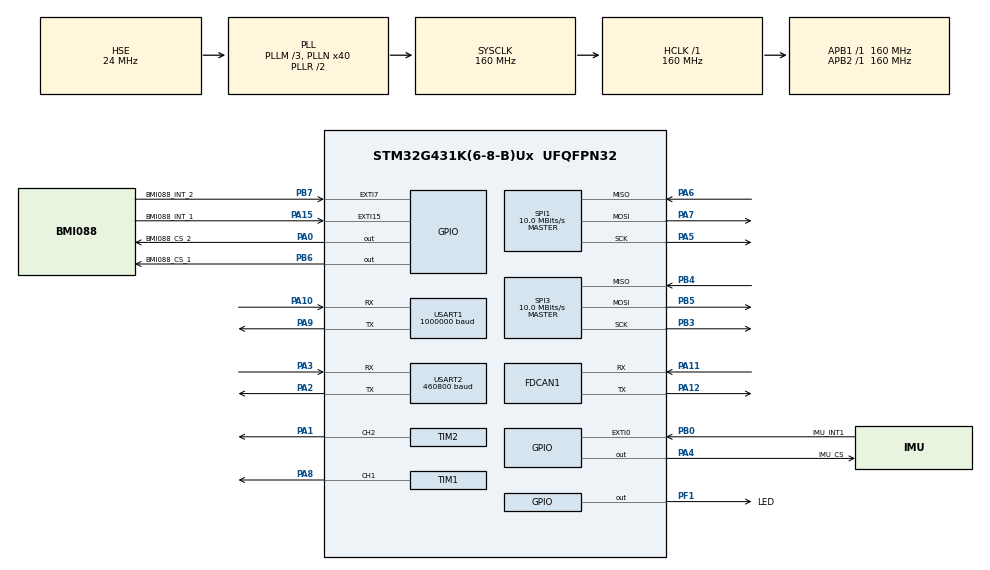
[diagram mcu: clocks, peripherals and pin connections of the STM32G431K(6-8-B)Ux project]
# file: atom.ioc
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Dma.Request0=USART2_RX
Dma.Request1=USART2_TX
Dma.Request2=SPI1_RX
Dma.Request3=SPI1_TX
Dma.Request4=USART1_RX
Dma.Request5=USART1_TX
Dma.Request6=SPI3_RX
Dma.Request7=SPI3_TX
Dma.SPI1_RX.2.Direction=DMA_PERIPH_TO_MEMORY
Dma.SPI1_RX.2.EventEnable=DISABLE
Dma.SPI1_RX.2.Instance=DMA1_Channel5
Dma.SPI1_RX.2.MemDataAlignment=DMA_MDATAALIGN_BYTE
Dma.SPI1_RX.2.MemInc=DMA_MINC_ENABLE
Dma.SPI1_RX.2.Mode=DMA_NORMAL
Dma.SPI1_RX.2.PeriphDataAlignment=DMA_PDATAALIGN_BYTE
Dma.SPI1_RX.2.PeriphInc=DMA_PINC_DISABLE
Dma.SPI1_RX.2.Polarity=HAL_DMAMUX_REQ_GEN_RISING
Dma.SPI1_RX.2.Priority=DMA_PRIORITY_LOW
Dma.SPI1_RX.2.RequestNumber=1
Dma.SPI1_RX.2.SignalID=NONE
Dma.SPI1_RX.2.SyncEnable=DISABLE
Dma.SPI1_RX.2.SyncPolarity=HAL_DMAMUX_SYNC_NO_EVENT
Dma.SPI1_RX.2.SyncRequestNumber=1
Dma.SPI1_RX.2.SyncSignalID=NONE
Dma.SPI1_TX.3.Direction=DMA_MEMORY_TO_PERIPH
Dma.SPI1_TX.3.EventEnable=DISABLE
Dma.SPI1_TX.3.Instance=DMA1_Channel6
Dma.SPI1_TX.3.MemDataAlignment=DMA_MDATAALIGN_BYTE
Dma.SPI1_TX.3.MemInc=DMA_MINC_ENABLE
Dma.SPI1_TX.3.Mode=DMA_NORMAL
Dma.SPI1_TX.3.PeriphDataAlignment=DMA_PDATAALIGN_BYTE
Dma.SPI1_TX.3.PeriphInc=DMA_PINC_DISABLE
Dma.SPI1_TX.3.Polarity=HAL_DMAMUX_REQ_GEN_RISING
Dma.SPI1_TX.3.Priority=DMA_PRIORITY_LOW
Dma.SPI1_TX.3.RequestNumber=1
Dma.SPI1_TX.3.SignalID=NONE
Dma.SPI1_TX.3.SyncEnable=DISABLE
Dma.SPI1_TX.3.SyncPolarity=HAL_DMAMUX_SYNC_NO_EVENT
Dma.SPI1_TX.3.SyncRequestNumber=1
Dma.SPI1_TX.3.SyncSignalID=NONE
Dma.SPI3_RX.6.Direction=DMA_PERIPH_TO_MEMORY
Dma.SPI3_RX.6.EventEnable=DISABLE
Dma.SPI3_RX.6.Instance=DMA1_Channel3
Dma.SPI3_RX.6.MemDataAlignment=DMA_MDATAALIGN_BYTE
Dma.SPI3_RX.6.MemInc=DMA_MINC_ENABLE
Dma.SPI3_RX.6.Mode=DMA_NORMAL
Dma.SPI3_RX.6.PeriphDataAlignment=DMA_PDATAALIGN_BYTE
Dma.SPI3_RX.6.PeriphInc=DMA_PINC_DISABLE
Dma.SPI3_RX.6.Polarity=HAL_DMAMUX_REQ_GEN_RISING
Dma.SPI3_RX.6.Priority=DMA_PRIORITY_LOW
Dma.SPI3_RX.6.RequestNumber=1
Dma.SPI3_RX.6.SignalID=NONE
Dma.SPI3_RX.6.SyncEnable=DISABLE
Dma.SPI3_RX.6.SyncPolarity=HAL_DMAMUX_SYNC_NO_EVENT
Dma.SPI3_RX.6.SyncRequestNumber=1
Dma.SPI3_RX.6.SyncSignalID=NONE
Dma.SPI3_TX.7.Direction=DMA_MEMORY_TO_PERIPH
Dma.SPI3_TX.7.EventEnable=DISABLE
Dma.SPI3_TX.7.Instance=DMA1_Channel4
Dma.SPI3_TX.7.MemDataAlignment=DMA_MDATAALIGN_BYTE
Dma.SPI3_TX.7.MemInc=DMA_MINC_ENABLE
Dma.SPI3_TX.7.Mode=DMA_NORMAL
Dma.SPI3_TX.7.PeriphDataAlignment=DMA_PDATAALIGN_BYTE
Dma.SPI3_TX.7.PeriphInc=DMA_PINC_DISABLE
Dma.SPI3_TX.7.Polarity=HAL_DMAMUX_REQ_GEN_RISING
Dma.SPI3_TX.7.Priority=DMA_PRIORITY_LOW
Dma.SPI3_TX.7.RequestNumber=1
Dma.SPI3_TX.7.SignalID=NONE
Dma.SPI3_TX.7.SyncEnable=DISABLE
Dma.SPI3_TX.7.SyncPolarity=HAL_DMAMUX_SYNC_NO_EVENT
Dma.SPI3_TX.7.SyncRequestNumber=1
Dma.SPI3_TX.7.SyncSignalID=NONE
Dma.USART1_RX.4.Direction=DMA_PERIPH_TO_MEMORY
Dma.USART1_RX.4.EventEnable=DISABLE
Dma.USART1_RX.4.Instance=DMA2_Channel1
Dma.USART1_RX.4.MemDataAlignment=DMA_MDATAALIGN_BYTE
Dma.USART1_RX.4.MemInc=DMA_MINC_ENABLE
Dma.USART1_RX.4.Mode=DMA_NORMAL
Dma.USART1_RX.4.PeriphDataAlignment=DMA_PDATAALIGN_BYTE
Dma.USART1_RX.4.PeriphInc=DMA_PINC_DISABLE
Dma.USART1_RX.4.Polarity=HAL_DMAMUX_REQ_GEN_RISING
Dma.USART1_RX.4.Priority=DMA_PRIORITY_LOW
Dma.USART1_RX.4.RequestNumber=1
Dma.USART1_RX.4.SignalID=NONE
Dma.USART1_RX.4.SyncEnable=DISABLE
Dma.USART1_RX.4.SyncPolarity=HAL_DMAMUX_SYNC_NO_EVENT
Dma.USART1_RX.4.SyncRequestNumber=1
Dma.USART1_RX.4.SyncSignalID=NONE
Dma.USART1_TX.5.Direction=DMA_MEMORY_TO_PERIPH
Dma.USART1_TX.5.EventEnable=DISABLE
Dma.USART1_TX.5.Instance=DMA2_Channel2
Dma.USART1_TX.5.MemDataAlignment=DMA_MDATAALIGN_BYTE
Dma.USART1_TX.5.MemInc=DMA_MINC_ENABLE
Dma.USART1_TX.5.Mode=DMA_NORMAL
Dma.USART1_TX.5.PeriphDataAlignment=DMA_PDATAALIGN_BYTE
Dma.USART1_TX.5.PeriphInc=DMA_PINC_DISABLE
Dma.USART1_TX.5.Polarity=HAL_DMAMUX_REQ_GEN_RISING
Dma.USART1_TX.5.Priority=DMA_PRIORITY_LOW
Dma.USART1_TX.5.RequestNumber=1
Dma.USART1_TX.5.SignalID=NONE
Dma.USART1_TX.5.SyncEnable=DISABLE
Dma.USART1_TX.5.SyncPolarity=HAL_DMAMUX_SYNC_NO_EVENT
Dma.USART1_TX.5.SyncRequestNumber=1
Dma.USART1_TX.5.SyncSignalID=NONE
Dma.USART2_RX.0.Direction=DMA_PERIPH_TO_MEMORY
Dma.USART2_RX.0.EventEnable=DISABLE
Dma.USART2_RX.0.Instance=DMA1_Channel1
Dma.USART2_RX.0.MemDataAlignment=DMA_MDATAALIGN_BYTE
Dma.USART2_RX.0.MemInc=DMA_MINC_ENABLE
Dma.USART2_RX.0.Mode=DMA_NORMAL
Dma.USART2_RX.0.PeriphDataAlignment=DMA_PDATAALIGN_BYTE
Dma.USART2_RX.0.PeriphInc=DMA_PINC_DISABLE
Dma.USART2_RX.0.Polarity=HAL_DMAMUX_REQ_GEN_RISING
Dma.USART2_RX.0.Priority=DMA_PRIORITY_LOW
Dma.USART2_RX.0.RequestNumber=1
Dma.USART2_RX.0.SignalID=NONE
Dma.USART2_RX.0.SyncEnable=DISABLE
Dma.USART2_RX.0.SyncPolarity=HAL_DMAMUX_SYNC_NO_EVENT
Dma.USART2_RX.0.SyncRequestNumber=1
Dma.USART2_RX.0.SyncSignalID=NONE
Dma.USART2_TX.1.Direction=DMA_MEMORY_TO_PERIPH
Dma.USART2_TX.1.EventEnable=DISABLE
Dma.USART2_TX.1.Instance=DMA1_Channel2
Dma.USART2_TX.1.MemDataAlignment=DMA_MDATAALIGN_BYTE
Dma.USART2_TX.1.MemInc=DMA_MINC_ENABLE
Dma.USART2_TX.1.Mode=DMA_NORMAL
Dma.USART2_TX.1.PeriphDataAlignment=DMA_PDATAALIGN_BYTE
Dma.USART2_TX.1.PeriphInc=DMA_PINC_DISABLE
Dma.USART2_TX.1.Polarity=HAL_DMAMUX_REQ_GEN_RISING
Dma.USART2_TX.1.Priority=DMA_PRIORITY_LOW
Dma.USART2_TX.1.RequestNumber=1
Dma.USART2_TX.1.SignalID=NONE
Dma.USART2_TX.1.SyncEnable=DISABLE
Dma.USART2_TX.1.SyncPolarity=HAL_DMAMUX_SYNC_NO_EVENT
Dma.USART2_TX.1.SyncRequestNumber=1
Dma.USART2_TX.1.SyncSignalID=NONE
FDCAN1.AutoRetransmission=ENABLE
FDCAN1.CalculateBaudRateNominal=1000000
FDCAN1.CalculateTimeBitNominal=1000
FDCAN1.CalculateTimeQuantumNominal=62.5
FDCAN1.DataPrescaler=2
FDCAN1.DataSyncJumpWidth=4
FDCAN1.DataTimeSeg1=13
FDCAN1.DataTimeSeg2=2
FDCAN1.ExtFiltersNbr=2
FDCAN1.FrameFormat=FDCAN_FRAME_FD_BRS
FDCAN1.Mode=FDCAN_MODE_NORMAL
FDCAN1.NominalPrescaler=10
FDCAN1.NominalSyncJumpWidth=4
FDCAN1.NominalTimeSeg1=13
FDCAN1.NominalTimeSeg2=2
FDCAN1.StdFiltersNbr=2
FDCAN1.TransmitPause=DISABLE
FREERTOS.INCLUDE_uxTaskPriorityGet=0
FREERTOS.INCLUDE_vTaskDelayUntil=1
FREERTOS.INCLUDE_vTaskDelete=0
FREERTOS.INCLUDE_vTaskPrioritySet=0
FREERTOS.INCLUDE_vTaskSuspend=0
FREERTOS.Tasks01=defaultTask,0,1024,StartDefaultTask,Default,NULL,Dynamic,NULL,NULL
FREERTOS.configENABLE_BACKWARD_COMPATIBILITY=0
FREERTOS.configENABLE_FPU=1
FREERTOS.configTOTAL_HEAP_SIZE=0x6000
FREERTOS.configUSE_COUNTING_SEMAPHORES=1
FREERTOS.configUSE_MUTEXES=1
Mcu.Family=STM32G4
Mcu.Name=STM32G431K(6-8-B)Ux
Mcu.Package=UFQFPN32
NVIC.DMA1_Channel1_IRQn=true\:5\:0\:true\:false\:true\:true\:false\:true\:true
NVIC.DMA1_Channel2_IRQn=true\:5\:0\:true\:false\:true\:true\:false\:true\:true
NVIC.DMA1_Channel3_IRQn=true\:5\:0\:true\:false\:true\:true\:false\:true\:true
NVIC.DMA1_Channel4_IRQn=true\:5\:0\:true\:false\:true\:true\:false\:true\:true
NVIC.DMA1_Channel5_IRQn=true\:5\:0\:true\:false\:true\:true\:false\:true\:true
NVIC.DMA1_Channel6_IRQn=true\:5\:0\:true\:false\:true\:true\:false\:true\:true
NVIC.DMA2_Channel1_IRQn=true\:5\:0\:true\:false\:true\:true\:false\:true\:true
NVIC.DMA2_Channel2_IRQn=true\:5\:0\:true\:false\:true\:true\:false\:true\:true
NVIC.EXTI0_IRQn=true\:5\:0\:true\:false\:true\:true\:true\:true\:true
NVIC.EXTI15_10_IRQn=true\:5\:0\:true\:false\:true\:true\:true\:true\:true
NVIC.EXTI9_5_IRQn=true\:5\:0\:true\:false\:true\:true\:true\:true\:true
NVIC.FDCAN1_IT0_IRQn=true\:5\:0\:true\:false\:true\:true\:true\:true\:true
NVIC.FDCAN1_IT1_IRQn=true\:5\:0\:true\:false\:true\:true\:true\:true\:true
NVIC.PriorityGroup=NVIC_PRIORITYGROUP_4
NVIC.RCC_IRQn=true\:5\:0\:true\:false\:true\:true\:true\:false\:true
NVIC.SPI1_IRQn=true\:5\:0\:true\:false\:true\:true\:true\:true\:true
NVIC.SPI3_IRQn=true\:5\:0\:true\:false\:true\:true\:true\:true\:true
NVIC.TIM1_BRK_TIM15_IRQn=true\:15\:0\:true\:false\:true\:false\:false\:true\:true
NVIC.TIM3_IRQn=true\:0\:0\:true\:false\:true\:false\:false\:true\:true
NVIC.TimeBase=TIM3_IRQn
NVIC.TimeBaseIP=TIM3
NVIC.USART1_IRQn=true\:5\:0\:true\:false\:true\:true\:true\:true\:true
NVIC.USART2_IRQn=true\:5\:0\:true\:false\:true\:true\:true\:true\:true
PA0.GPIO_Label=BMI088_CS_2
PA0.PinState=GPIO_PIN_SET
PA0.Signal=GPIO_Output
PA1.Signal=S_TIM2_CH2
PA10.Mode=Asynchronous
PA10.Signal=USART1_RX
PA11.Mode=FDCAN_Activate
PA11.Signal=FDCAN1_RX
PA12.Mode=FDCAN_Activate
PA12.Signal=FDCAN1_TX
PA13.Mode=Serial_Wire
PA13.Signal=SYS_JTMS-SWDIO
PA14.Mode=Serial_Wire
PA14.Signal=SYS_JTCK-SWCLK
PA15.GPIO_Label=BMI088_INT_1
PA15.GPIO_ModeDefaultEXTI=GPIO_MODE_IT_FALLING
PA15.Signal=GPXTI15
PA2.Mode=Asynchronous
PA2.Signal=USART2_TX
PA3.Mode=Asynchronous
PA3.Signal=USART2_RX
PA4.GPIO_Label=IMU_CS
PA4.PinState=GPIO_PIN_SET
PA4.Signal=GPIO_Output
PA5.GPIO_PuPd=GPIO_PULLUP
PA5.Mode=Full_Duplex_Master
PA5.Signal=SPI1_SCK
PA6.GPIO_PuPd=GPIO_PULLDOWN
PA6.Mode=Full_Duplex_Master
PA6.Signal=SPI1_MISO
PA7.GPIO_PuPd=GPIO_PULLUP
PA7.Mode=Full_Duplex_Master
PA7.Signal=SPI1_MOSI
PA8.Signal=S_TIM1_CH1
PA9.Mode=Asynchronous
PA9.Signal=USART1_TX
PB0.GPIO_Label=IMU_INT1
PB0.GPIO_ModeDefaultEXTI=GPIO_MODE_IT_FALLING
PB0.GPIO_PuPd=GPIO_PULLDOWN
PB0.Signal=GPXTI0
PB3.Mode=Full_Duplex_Master
PB3.Signal=SPI3_SCK
PB4.Mode=Full_Duplex_Master
PB4.Signal=SPI3_MISO
PB5.Mode=Full_Duplex_Master
PB5.Signal=SPI3_MOSI
PB6.GPIO_Label=BMI088_CS_1
PB6.PinState=GPIO_PIN_SET
PB6.Signal=GPIO_Output
PB7.GPIO_Label=BMI088_INT_2
PB7.GPIO_ModeDefaultEXTI=GPIO_MODE_IT_FALLING
PB7.Signal=GPXTI7
PF0-OSC_IN.Mode=HSE-External-Clock-Source
PF0-OSC_IN.Signal=RCC_OSC_IN
PF1-OSC_OUT.GPIO_Label=LED
PF1-OSC_OUT.Signal=GPIO_Output
ProjectManager.HeapSize=0x200
ProjectManager.StackSize=0x400
ProjectManager.TargetToolchain=CMake
RCC.ADC12Freq_Value=160000000
RCC.AHBFreq_Value=160000000
RCC.APB1Freq_Value=160000000
RCC.APB1TimFreq_Value=160000000
RCC.APB2Freq_Value=160000000
RCC.APB2TimFreq_Value=160000000
RCC.CortexFreq_Value=160000000
RCC.EXTERNAL_CLOCK_VALUE=12288000
RCC.HCLKFreq_Value=160000000
RCC.HSE_VALUE=24000000
RCC.HSI48_VALUE=48000000
RCC.HSI_VALUE=16000000
RCC.LSE_VALUE=32768
RCC.PLLM=RCC_PLLM_DIV3
RCC.PLLN=40
RCC.PLLSourceVirtual=RCC_PLLSOURCE_HSE
RCC.SYSCLKFreq_VALUE=160000000
RCC.SYSCLKSource=RCC_SYSCLKSOURCE_PLLCLK
RCC.USBFreq_Value=160000000
RCC.VCOOutputFreq_Value=320000000
SH.S_TIM1_CH1.0=TIM1_CH1,PWM Generation1 CH1
SH.S_TIM2_CH2.0=TIM2_CH2,PWM Generation2 CH2
SPI1.BaudRatePrescaler=SPI_BAUDRATEPRESCALER_16
SPI1.CLKPhase=SPI_PHASE_1EDGE
SPI1.CLKPolarity=SPI_POLARITY_LOW
SPI1.CalculateBaudRate=10.0 MBits/s
SPI1.DataSize=SPI_DATASIZE_8BIT
SPI1.Direction=SPI_DIRECTION_2LINES
SPI1.Mode=SPI_MODE_MASTER
SPI1.VirtualType=VM_MASTER
SPI3.BaudRatePrescaler=SPI_BAUDRATEPRESCALER_16
SPI3.CLKPhase=SPI_PHASE_2EDGE
SPI3.CLKPolarity=SPI_POLARITY_HIGH
SPI3.CalculateBaudRate=10.0 MBits/s
SPI3.DataSize=SPI_DATASIZE_8BIT
SPI3.Direction=SPI_DIRECTION_2LINES
SPI3.Mode=SPI_MODE_MASTER
SPI3.VirtualType=VM_MASTER
TIM1.Channel-PWM\ Generation1\ CH1=TIM_CHANNEL_1
TIM1.PeriodNoDither=99
TIM2.Channel-PWM\ Generation2\ CH2=TIM_CHANNEL_2
TIM2.PeriodNoDither=99
TIM8.AutoReloadPreload=TIM_AUTORELOAD_PRELOAD_DISABLE
TIM8.ClockDivision=TIM_CLOCKDIVISION_DIV1
TIM8.Prescaler=159
USART1.BaudRate=1000000
USART1.VirtualMode-Asynchronous=VM_ASYNC
USART2.BaudRate=460800
USART2.VirtualMode-Asynchronous=VM_ASYNC
VP_FREERTOS_VS_CMSIS_V1.Mode=CMSIS_V1
VP_SYS_VS_DBSignals.Mode=DisableDeadBatterySignals
VP_SYS_VS_tim3.Mode=TIM3
VP_TIM8_VS_ClockSourceINT.Mode=Internal
board=custom

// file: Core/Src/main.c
/* USER CODE BEGIN Header */
/**
  ******************************************************************************
  * @file           : main.c
  * @brief          : Main program body
  ******************************************************************************
  * @attention
  *
  * Copyright (c) 2025 STMicroelectronics.
  * All rights reserved.
  *
  * This software is licensed under terms that can be found in the LICENSE file
  * in the root directory of this software component.
  * If no LICENSE file comes with this software, it is provided AS-IS.
  *
  ******************************************************************************
  */
/* USER CODE END Header */
#include "main.h"
#include "cmsis_os.h"

FDCAN_HandleTypeDef hfdcan1;

SPI_HandleTypeDef hspi1;
SPI_HandleTypeDef hspi3;
DMA_HandleTypeDef hdma_spi1_rx;
DMA_HandleTypeDef hdma_spi1_tx;
DMA_HandleTypeDef hdma_spi3_rx;
DMA_HandleTypeDef hdma_spi3_tx;

TIM_HandleTypeDef htim1;
TIM_HandleTypeDef htim2;
TIM_HandleTypeDef htim8;

UART_HandleTypeDef huart1;
UART_HandleTypeDef huart2;
DMA_HandleTypeDef hdma_usart1_rx;
DMA_HandleTypeDef hdma_usart1_tx;
DMA_HandleTypeDef hdma_usart2_rx;
DMA_HandleTypeDef hdma_usart2_tx;

osThreadId defaultTaskHandle;

void SystemClock_Config(void);
void StartDefaultTask(void const * argument);

/* USER CODE BEGIN 0 */
__attribute__((section(".reboot_in_bootloader_section"), used)) static void
bsp_reboot_in_bootloader(void);
/* USER CODE END 0 */

int main(void)
{

  /* MCU Configuration--------------------------------------------------------*/

  /* Reset of all peripherals, Initializes the Flash interface and the Systick. */
  HAL_Init();

  /* Configure the system clock */
  SystemClock_Config();

  /* Initialize all configured peripherals */
  MX_GPIO_Init();
  MX_DMA_Init();
  MX_FDCAN1_Init();
  MX_SPI1_Init();
  MX_USART2_UART_Init();
  MX_USART1_UART_Init();
  MX_TIM2_Init();
  MX_SPI3_Init();
  MX_TIM1_Init();
  MX_TIM8_Init();

  /* Create the thread(s) */
  /* definition and creation of defaultTask */
  osThreadDef(defaultTask, StartDefaultTask, osPriorityNormal, 0, 1024);
  defaultTaskHandle = osThreadCreate(osThread(defaultTask), NULL);

  /* Start scheduler */
  osKernelStart();

  /* We should never get here as control is now taken by the scheduler */

  /* Infinite loop */
  while (1)
  {

  }
}

void SystemClock_Config(void)
{
  RCC_OscInitTypeDef RCC_OscInitStruct = {0};
  RCC_ClkInitTypeDef RCC_ClkInitStruct = {0};

  /** Configure the main internal regulator output voltage
  */
  HAL_PWREx_ControlVoltageScaling(PWR_REGULATOR_VOLTAGE_SCALE1_BOOST);

  /** Initializes the RCC Oscillators according to the specified parameters
  * in the RCC_OscInitTypeDef structure.
  */
  RCC_OscInitStruct.OscillatorType = RCC_OSCILLATORTYPE_HSE;
  RCC_OscInitStruct.HSEState = RCC_HSE_BYPASS;
  RCC_OscInitStruct.PLL.PLLState = RCC_PLL_ON;
  RCC_OscInitStruct.PLL.PLLSource = RCC_PLLSOURCE_HSE;
  RCC_OscInitStruct.PLL.PLLM = RCC_PLLM_DIV3;
  RCC_OscInitStruct.PLL.PLLN = 40;
  RCC_OscInitStruct.PLL.PLLP = RCC_PLLP_DIV2;
  RCC_OscInitStruct.PLL.PLLQ = RCC_PLLQ_DIV2;
  RCC_OscInitStruct.PLL.PLLR = RCC_PLLR_DIV2;
  if (HAL_RCC_OscConfig(&RCC_OscInitStruct) != HAL_OK)
  {
    Error_Handler();
  }

  /** Initializes the CPU, AHB and APB buses clocks
  */
  RCC_ClkInitStruct.ClockType = RCC_CLOCKTYPE_HCLK|RCC_CLOCKTYPE_SYSCLK
                              |RCC_CLOCKTYPE_PCLK1|RCC_CLOCKTYPE_PCLK2;
  RCC_ClkInitStruct.SYSCLKSource = RCC_SYSCLKSOURCE_PLLCLK;
  RCC_ClkInitStruct.AHBCLKDivider = RCC_SYSCLK_DIV1;
  RCC_ClkInitStruct.APB1CLKDivider = RCC_HCLK_DIV1;
  RCC_ClkInitStruct.APB2CLKDivider = RCC_HCLK_DIV1;

  if (HAL_RCC_ClockConfig(&RCC_ClkInitStruct, FLASH_LATENCY_4) != HAL_OK)
  {
    Error_Handler();
  }
}

void MX_FDCAN1_Init(void)
{

  hfdcan1.Instance = FDCAN1;
  hfdcan1.Init.ClockDivider = FDCAN_CLOCK_DIV1;
  hfdcan1.Init.FrameFormat = FDCAN_FRAME_FD_BRS;
  hfdcan1.Init.Mode = FDCAN_MODE_NORMAL;
  hfdcan1.Init.AutoRetransmission = ENABLE;
  hfdcan1.Init.TransmitPause = DISABLE;
  hfdcan1.Init.ProtocolException = DISABLE;
  hfdcan1.Init.NominalPrescaler = 10;
  hfdcan1.Init.NominalSyncJumpWidth = 4;
  hfdcan1.Init.NominalTimeSeg1 = 13;
  hfdcan1.Init.NominalTimeSeg2 = 2;
  hfdcan1.Init.DataPrescaler = 2;
  hfdcan1.Init.DataSyncJumpWidth = 4;
  hfdcan1.Init.DataTimeSeg1 = 13;
  hfdcan1.Init.DataTimeSeg2 = 2;
  hfdcan1.Init.StdFiltersNbr = 2;
  hfdcan1.Init.ExtFiltersNbr = 2;
  hfdcan1.Init.TxFifoQueueMode = FDCAN_TX_FIFO_OPERATION;
  if (HAL_FDCAN_Init(&hfdcan1) != HAL_OK)
  {
    Error_Handler();
  }

}

void MX_SPI1_Init(void)
{

  /* SPI1 parameter configuration*/
  hspi1.Instance = SPI1;
  hspi1.Init.Mode = SPI_MODE_MASTER;
  hspi1.Init.Direction = SPI_DIRECTION_2LINES;
  hspi1.Init.DataSize = SPI_DATASIZE_8BIT;
  hspi1.Init.CLKPolarity = SPI_POLARITY_LOW;
  hspi1.Init.CLKPhase = SPI_PHASE_1EDGE;
  hspi1.Init.NSS = SPI_NSS_SOFT;
  hspi1.Init.BaudRatePrescaler = SPI_BAUDRATEPRESCALER_16;
  hspi1.Init.FirstBit = SPI_FIRSTBIT_MSB;
  hspi1.Init.TIMode = SPI_TIMODE_DISABLE;
  hspi1.Init.CRCCalculation = SPI_CRCCALCULATION_DISABLE;
  hspi1.Init.CRCPolynomial = 7;
  hspi1.Init.CRCLength = SPI_CRC_LENGTH_DATASIZE;
  hspi1.Init.NSSPMode = SPI_NSS_PULSE_ENABLE;
  if (HAL_SPI_Init(&hspi1) != HAL_OK)
  {
    Error_Handler();
  }

}

void MX_SPI3_Init(void)
{

  /* SPI3 parameter configuration*/
  hspi3.Instance = SPI3;
  hspi3.Init.Mode = SPI_MODE_MASTER;
  hspi3.Init.Direction = SPI_DIRECTION_2LINES;
  hspi3.Init.DataSize = SPI_DATASIZE_8BIT;
  hspi3.Init.CLKPolarity = SPI_POLARITY_HIGH;
  hspi3.Init.CLKPhase = SPI_PHASE_2EDGE;
  hspi3.Init.NSS = SPI_NSS_SOFT;
  hspi3.Init.BaudRatePrescaler = SPI_BAUDRATEPRESCALER_16;
  hspi3.Init.FirstBit = SPI_FIRSTBIT_MSB;
  hspi3.Init.TIMode = SPI_TIMODE_DISABLE;
  hspi3.Init.CRCCalculation = SPI_CRCCALCULATION_DISABLE;
  hspi3.Init.CRCPolynomial = 7;
  hspi3.Init.CRCLength = SPI_CRC_LENGTH_DATASIZE;
  hspi3.Init.NSSPMode = SPI_NSS_PULSE_DISABLE;
  if (HAL_SPI_Init(&hspi3) != HAL_OK)
  {
    Error_Handler();
  }

}

void MX_TIM1_Init(void)
{

  TIM_MasterConfigTypeDef sMasterConfig = {0};
  TIM_OC_InitTypeDef sConfigOC = {0};
  TIM_BreakDeadTimeConfigTypeDef sBreakDeadTimeConfig = {0};

  htim1.Instance = TIM1;
  htim1.Init.Prescaler = 0;
  htim1.Init.CounterMode = TIM_COUNTERMODE_UP;
  htim1.Init.Period = 99;
  htim1.Init.ClockDivision = TIM_CLOCKDIVISION_DIV1;
  htim1.Init.RepetitionCounter = 0;
  htim1.Init.AutoReloadPreload = TIM_AUTORELOAD_PRELOAD_DISABLE;
  if (HAL_TIM_PWM_Init(&htim1) != HAL_OK)
  {
    Error_Handler();
  }
  sMasterConfig.MasterOutputTrigger = TIM_TRGO_RESET;
  sMasterConfig.MasterOutputTrigger2 = TIM_TRGO2_RESET;
  sMasterConfig.MasterSlaveMode = TIM_MASTERSLAVEMODE_DISABLE;
  if (HAL_TIMEx_MasterConfigSynchronization(&htim1, &sMasterConfig) != HAL_OK)
  {
    Error_Handler();
  }
  sConfigOC.OCMode = TIM_OCMODE_PWM1;
  sConfigOC.Pulse = 0;
  sConfigOC.OCPolarity = TIM_OCPOLARITY_HIGH;
  sConfigOC.OCNPolarity = TIM_OCNPOLARITY_HIGH;
  sConfigOC.OCFastMode = TIM_OCFAST_DISABLE;
  sConfigOC.OCIdleState = TIM_OCIDLESTATE_RESET;
  sConfigOC.OCNIdleState = TIM_OCNIDLESTATE_RESET;
  if (HAL_TIM_PWM_ConfigChannel(&htim1, &sConfigOC, TIM_CHANNEL_1) != HAL_OK)
  {
    Error_Handler();
  }
  sBreakDeadTimeConfig.OffStateRunMode = TIM_OSSR_DISABLE;
  sBreakDeadTimeConfig.OffStateIDLEMode = TIM_OSSI_DISABLE;
  sBreakDeadTimeConfig.LockLevel = TIM_LOCKLEVEL_OFF;
  sBreakDeadTimeConfig.DeadTime = 0;
  sBreakDeadTimeConfig.BreakState = TIM_BREAK_DISABLE;
  sBreakDeadTimeConfig.BreakPolarity = TIM_BREAKPOLARITY_HIGH;
  sBreakDeadTimeConfig.BreakFilter = 0;
  sBreakDeadTimeConfig.BreakAFMode = TIM_BREAK_AFMODE_INPUT;
  sBreakDeadTimeConfig.Break2State = TIM_BREAK2_DISABLE;
  sBreakDeadTimeConfig.Break2Polarity = TIM_BREAK2POLARITY_HIGH;
  sBreakDeadTimeConfig.Break2Filter = 0;
  sBreakDeadTimeConfig.Break2AFMode = TIM_BREAK_AFMODE_INPUT;
  sBreakDeadTimeConfig.AutomaticOutput = TIM_AUTOMATICOUTPUT_DISABLE;
  if (HAL_TIMEx_ConfigBreakDeadTime(&htim1, &sBreakDeadTimeConfig) != HAL_OK)
  {
    Error_Handler();
  }
  HAL_TIM_MspPostInit(&htim1);

}

void MX_TIM2_Init(void)
{

  TIM_MasterConfigTypeDef sMasterConfig = {0};
  TIM_OC_InitTypeDef sConfigOC = {0};

  htim2.Instance = TIM2;
  htim2.Init.Prescaler = 0;
  htim2.Init.CounterMode = TIM_COUNTERMODE_UP;
  htim2.Init.Period = 99;
  htim2.Init.ClockDivision = TIM_CLOCKDIVISION_DIV1;
  htim2.Init.AutoReloadPreload = TIM_AUTORELOAD_PRELOAD_DISABLE;
  if (HAL_TIM_PWM_Init(&htim2) != HAL_OK)
  {
    Error_Handler();
  }
  sMasterConfig.MasterOutputTrigger = TIM_TRGO_RESET;
  sMasterConfig.MasterSlaveMode = TIM_MASTERSLAVEMODE_DISABLE;
  if (HAL_TIMEx_MasterConfigSynchronization(&htim2, &sMasterConfig) != HAL_OK)
  {
    Error_Handler();
  }
  sConfigOC.OCMode = TIM_OCMODE_PWM1;
  sConfigOC.Pulse = 0;
  sConfigOC.OCPolarity = TIM_OCPOLARITY_HIGH;
  sConfigOC.OCFastMode = TIM_OCFAST_DISABLE;
  if (HAL_TIM_PWM_ConfigChannel(&htim2, &sConfigOC, TIM_CHANNEL_2) != HAL_OK)
  {
    Error_Handler();
  }
  HAL_TIM_MspPostInit(&htim2);

}

void MX_TIM8_Init(void)
{

  TIM_ClockConfigTypeDef sClockSourceConfig = {0};
  TIM_MasterConfigTypeDef sMasterConfig = {0};

  htim8.Instance = TIM8;
  htim8.Init.Prescaler = 159;
  htim8.Init.CounterMode = TIM_COUNTERMODE_UP;
  htim8.Init.Period = 65535;
  htim8.Init.ClockDivision = TIM_CLOCKDIVISION_DIV1;
  htim8.Init.RepetitionCounter = 0;
  htim8.Init.AutoReloadPreload = TIM_AUTORELOAD_PRELOAD_DISABLE;
  if (HAL_TIM_Base_Init(&htim8) != HAL_OK)
  {
    Error_Handler();
  }
  sClockSourceConfig.ClockSource = TIM_CLOCKSOURCE_INTERNAL;
  if (HAL_TIM_ConfigClockSource(&htim8, &sClockSourceConfig) != HAL_OK)
  {
    Error_Handler();
  }
  sMasterConfig.MasterOutputTrigger = TIM_TRGO_RESET;
  sMasterConfig.MasterOutputTrigger2 = TIM_TRGO2_RESET;
  sMasterConfig.MasterSlaveMode = TIM_MASTERSLAVEMODE_DISABLE;
  if (HAL_TIMEx_MasterConfigSynchronization(&htim8, &sMasterConfig) != HAL_OK)
  {
    Error_Handler();
  }

}

void MX_USART1_UART_Init(void)
{

  huart1.Instance = USART1;
  huart1.Init.BaudRate = 1000000;
  huart1.Init.WordLength = UART_WORDLENGTH_8B;
  huart1.Init.StopBits = UART_STOPBITS_1;
  huart1.Init.Parity = UART_PARITY_NONE;
  huart1.Init.Mode = UART_MODE_TX_RX;
  huart1.Init.HwFlowCtl = UART_HWCONTROL_NONE;
  huart1.Init.OverSampling = UART_OVERSAMPLING_16;
  huart1.Init.OneBitSampling = UART_ONE_BIT_SAMPLE_DISABLE;
  huart1.Init.ClockPrescaler = UART_PRESCALER_DIV1;
  huart1.AdvancedInit.AdvFeatureInit = UART_ADVFEATURE_NO_INIT;
  if (HAL_UART_Init(&huart1) != HAL_OK)
  {
    Error_Handler();
  }
  if (HAL_UARTEx_SetTxFifoThreshold(&huart1, UART_TXFIFO_THRESHOLD_1_8) != HAL_OK)
  {
    Error_Handler();
  }
  if (HAL_UARTEx_SetRxFifoThreshold(&huart1, UART_RXFIFO_THRESHOLD_1_8) != HAL_OK)
  {
    Error_Handler();
  }
  if (HAL_UARTEx_DisableFifoMode(&huart1) != HAL_OK)
  {
    Error_Handler();
  }

}

void MX_USART2_UART_Init(void)
{

  huart2.Instance = USART2;
  huart2.Init.BaudRate = 460800;
  huart2.Init.WordLength = UART_WORDLENGTH_8B;
  huart2.Init.StopBits = UART_STOPBITS_1;
  huart2.Init.Parity = UART_PARITY_NONE;
  huart2.Init.Mode = UART_MODE_TX_RX;
  huart2.Init.HwFlowCtl = UART_HWCONTROL_NONE;
  huart2.Init.OverSampling = UART_OVERSAMPLING_16;
  huart2.Init.OneBitSampling = UART_ONE_BIT_SAMPLE_DISABLE;
  huart2.Init.ClockPrescaler = UART_PRESCALER_DIV1;
  huart2.AdvancedInit.AdvFeatureInit = UART_ADVFEATURE_NO_INIT;
  if (HAL_UART_Init(&huart2) != HAL_OK)
  {
    Error_Handler();
  }
  if (HAL_UARTEx_SetTxFifoThreshold(&huart2, UART_TXFIFO_THRESHOLD_1_8) != HAL_OK)
  {
    Error_Handler();
  }
  if (HAL_UARTEx_SetRxFifoThreshold(&huart2, UART_RXFIFO_THRESHOLD_1_8) != HAL_OK)
  {
    Error_Handler();
  }
  if (HAL_UARTEx_DisableFifoMode(&huart2) != HAL_OK)
  {
    Error_Handler();
  }

}

void MX_DMA_Init(void)
{

  /* DMA controller clock enable */
  __HAL_RCC_DMAMUX1_CLK_ENABLE();
  __HAL_RCC_DMA1_CLK_ENABLE();
  __HAL_RCC_DMA2_CLK_ENABLE();

  /* DMA interrupt init */
  /* DMA1_Channel1_IRQn interrupt configuration */
  HAL_NVIC_SetPriority(DMA1_Channel1_IRQn, 5, 0);
  HAL_NVIC_EnableIRQ(DMA1_Channel1_IRQn);
  /* DMA1_Channel2_IRQn interrupt configuration */
  HAL_NVIC_SetPriority(DMA1_Channel2_IRQn, 5, 0);
  HAL_NVIC_EnableIRQ(DMA1_Channel2_IRQn);
  /* DMA1_Channel3_IRQn interrupt configuration */
  HAL_NVIC_SetPriority(DMA1_Channel3_IRQn, 5, 0);
  HAL_NVIC_EnableIRQ(DMA1_Channel3_IRQn);
  /* DMA1_Channel4_IRQn interrupt configuration */
  HAL_NVIC_SetPriority(DMA1_Channel4_IRQn, 5, 0);
  HAL_NVIC_EnableIRQ(DMA1_Channel4_IRQn);
  /* DMA1_Channel5_IRQn interrupt configuration */
  HAL_NVIC_SetPriority(DMA1_Channel5_IRQn, 5, 0);
  HAL_NVIC_EnableIRQ(DMA1_Channel5_IRQn);
  /* DMA1_Channel6_IRQn interrupt configuration */
  HAL_NVIC_SetPriority(DMA1_Channel6_IRQn, 5, 0);
  HAL_NVIC_EnableIRQ(DMA1_Channel6_IRQn);
  /* DMA2_Channel1_IRQn interrupt configuration */
  HAL_NVIC_SetPriority(DMA2_Channel1_IRQn, 5, 0);
  HAL_NVIC_EnableIRQ(DMA2_Channel1_IRQn);
  /* DMA2_Channel2_IRQn interrupt configuration */
  HAL_NVIC_SetPriority(DMA2_Channel2_IRQn, 5, 0);
  HAL_NVIC_EnableIRQ(DMA2_Channel2_IRQn);

}

void MX_GPIO_Init(void)
{
  GPIO_InitTypeDef GPIO_InitStruct = {0};

  /* GPIO Ports Clock Enable */
  __HAL_RCC_GPIOF_CLK_ENABLE();
  __HAL_RCC_GPIOA_CLK_ENABLE();
  __HAL_RCC_GPIOB_CLK_ENABLE();

  /*Configure GPIO pin Output Level */
  HAL_GPIO_WritePin(LED_GPIO_Port, LED_Pin, GPIO_PIN_RESET);

  /*Configure GPIO pin Output Level */
  HAL_GPIO_WritePin(GPIOA, BMI088_CS_2_Pin|IMU_CS_Pin, GPIO_PIN_SET);

  /*Configure GPIO pin Output Level */
  HAL_GPIO_WritePin(BMI088_CS_1_GPIO_Port, BMI088_CS_1_Pin, GPIO_PIN_SET);

  /*Configure GPIO pin : LED_Pin */
  GPIO_InitStruct.Pin = LED_Pin;
  GPIO_InitStruct.Mode = GPIO_MODE_OUTPUT_PP;
  GPIO_InitStruct.Pull = GPIO_NOPULL;
  GPIO_InitStruct.Speed = GPIO_SPEED_FREQ_LOW;
  HAL_GPIO_Init(LED_GPIO_Port, &GPIO_InitStruct);

  /*Configure GPIO pins : BMI088_CS_2_Pin IMU_CS_Pin */
  GPIO_InitStruct.Pin = BMI088_CS_2_Pin|IMU_CS_Pin;
  GPIO_InitStruct.Mode = GPIO_MODE_OUTPUT_PP;
  GPIO_InitStruct.Pull = GPIO_NOPULL;
  GPIO_InitStruct.Speed = GPIO_SPEED_FREQ_LOW;
  HAL_GPIO_Init(GPIOA, &GPIO_InitStruct);

  /*Configure GPIO pin : IMU_INT1_Pin */
  GPIO_InitStruct.Pin = IMU_INT1_Pin;
  GPIO_InitStruct.Mode = GPIO_MODE_IT_FALLING;
  GPIO_InitStruct.Pull = GPIO_PULLDOWN;
  HAL_GPIO_Init(IMU_INT1_GPIO_Port, &GPIO_InitStruct);

  /*Configure GPIO pin : BMI088_INT_1_Pin */
  GPIO_InitStruct.Pin = BMI088_INT_1_Pin;
  GPIO_InitStruct.Mode = GPIO_MODE_IT_FALLING;
  GPIO_InitStruct.Pull = GPIO_NOPULL;
  HAL_GPIO_Init(BMI088_INT_1_GPIO_Port, &GPIO_InitStruct);

  /*Configure GPIO pin : BMI088_CS_1_Pin */
  GPIO_InitStruct.Pin = BMI088_CS_1_Pin;
  GPIO_InitStruct.Mode = GPIO_MODE_OUTPUT_PP;
  GPIO_InitStruct.Pull = GPIO_NOPULL;
  GPIO_InitStruct.Speed = GPIO_SPEED_FREQ_LOW;
  HAL_GPIO_Init(BMI088_CS_1_GPIO_Port, &GPIO_InitStruct);

  /*Configure GPIO pin : BMI088_INT_2_Pin */
  GPIO_InitStruct.Pin = BMI088_INT_2_Pin;
  GPIO_InitStruct.Mode = GPIO_MODE_IT_FALLING;
  GPIO_InitStruct.Pull = GPIO_NOPULL;
  HAL_GPIO_Init(BMI088_INT_2_GPIO_Port, &GPIO_InitStruct);

  /* EXTI interrupt init*/
  HAL_NVIC_SetPriority(EXTI0_IRQn, 5, 0);
  HAL_NVIC_EnableIRQ(EXTI0_IRQn);

  HAL_NVIC_SetPriority(EXTI9_5_IRQn, 5, 0);
  HAL_NVIC_EnableIRQ(EXTI9_5_IRQn);

  HAL_NVIC_SetPriority(EXTI15_10_IRQn, 5, 0);
  HAL_NVIC_EnableIRQ(EXTI15_10_IRQn);

}

/* USER CODE BEGIN 4 */
#include "app_main.h"
/* USER CODE END 4 */

void StartDefaultTask(void const * argument)
{
  /* USER CODE BEGIN 5 */
  app_main();
  /* Infinite loop */
  for(;;)
  {
    osDelay(1);
  }
  /* USER CODE END 5 */
}

void HAL_TIM_PeriodElapsedCallback(TIM_HandleTypeDef *htim)
{
  if (htim->Instance == TIM3)
  {
    HAL_IncTick();
  }
}

void Error_Handler(void)
{
  __disable_irq();
  while (1)
  {
  }
}
